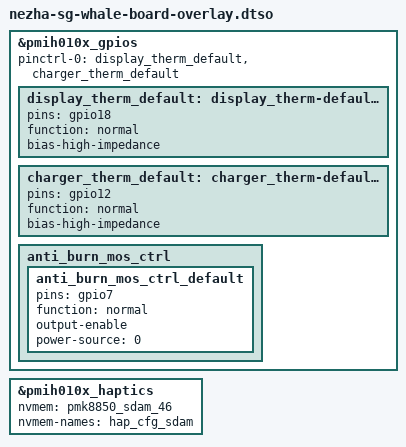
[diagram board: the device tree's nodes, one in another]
// SPDX-License-Identifier: GPL-2.0-only
#include "nezha-sg-whale-input-overlay.dtso"
#include "nezha-platform.dtsi"
#include "nezha-sm8850-regulator.dtsi"
#include "nezha-charger-common.dtsi"
#include "audio/canoe-audio.dtsi"

&pmih010x_gpios {
	pinctrl-0 = <&display_therm_default>, <&charger_therm_default>;
	pinctrl-names = "default";

	display_therm_default: display_therm-default-state {
		pins = "gpio18";
		function = "normal";
		bias-high-impedance;
	};

	charger_therm_default: charger_therm-default-state {
		pins = "gpio12";
		function = "normal";
		bias-high-impedance;
	};

	anti_burn_mos_ctrl {
		anti_burn_mos_ctrl_default: anti_burn_mos_ctrl_default {
			pins = "gpio7";
			function = "normal";
			output-enable;
			//drive-strength = <2>;
			power-source = <0>;
		};
	};
};

&pmih010x_haptics {
	nvmem = <&pmk8850_sdam_46>;
	nvmem-names = "hap_cfg_sdam";
};

#include "nezha-sm8850-dxs702.dtsi"
#include "nezha-sm8850-tof.dtsi"
